# CC2340R5 register map
File version: 1.0
CPU: CM0P 1.0, other endian, MPU, FPU, 3 interrupt priority bits
Registers are 32-bit, read-write, reset 0x0 unless marked. A register's access mark holds for its fields unless they carry their own. Offsets are from the block's base; [hi:lo] are bit positions; {n}, {i} and the like mark numbered series; 'fields as' and 'values as' point back to an identical list.

## ADC — ADC (Analog to Digital Converter) module
Base 0x40050000
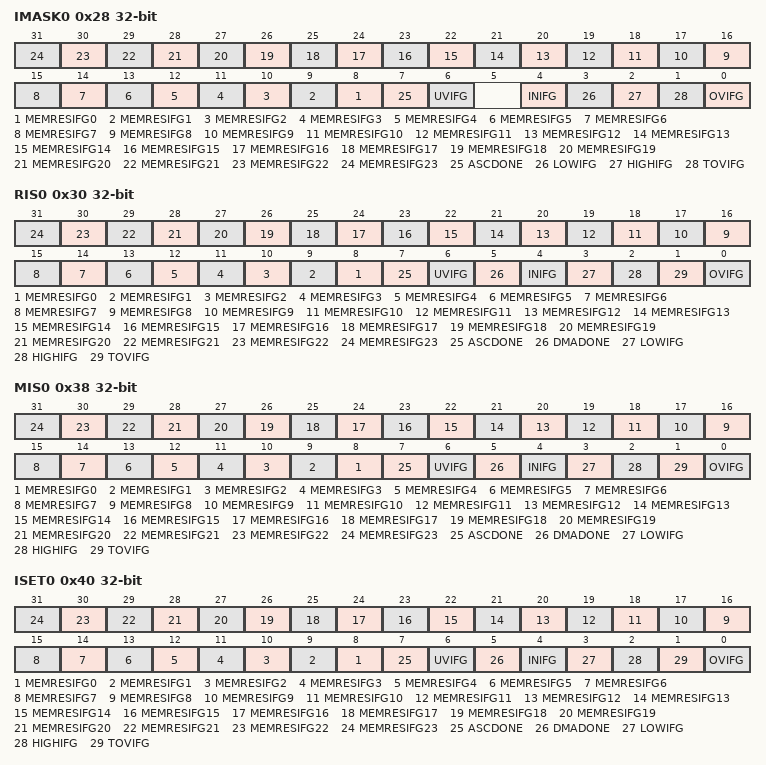
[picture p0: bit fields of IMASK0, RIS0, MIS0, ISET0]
0x28 IMASK0 — Interrupt mask. This register selects interrupt sources which are allowed to pass from RIS0 to MIS0 when the corresponding bit-fields are set to 1.
  [all] fields
    1=ENA (Enable interrupt mask); 0=DIS (Disable interrupt mask)
  [n+8] MEMRESIFG{n} (n=0..23) — [{n+8}:{n+8}] MEMRES{n} conversion result interrupt mask.
  [7] ASCDONE — [7:7] Mask for ASC done raw interrupt flag
  [6] UVIFG — [6:6] Conversion underflow interrupt mask
  [4] INIFG — [4:4] In-range comparator interrupt mask.
  [3] LOWIFG — [3:3] Low threshold compare interrupt mask
  [2] HIGHIFG — [2:2] High threshold compare interrupt mask
  [1] TOVIFG — [1:1] Sequence conversion time overflow interrupt mask
  [0] OVIFG — [0:0] Conversion overflow interrupt mask
0x30 RIS0 — Raw interrupt status. This register reflects the state of all pending interrupts, regardless of masking. This register allows the user to implement a poll scheme. A flag set in this register can be cleared by writing 1 to the corresponding ICLR0 register bit.
  [n+8] MEMRESIFG{n} (n=0..23) — [{n+8}:{n+8}] Raw interrupt status for MEMRES{n}. This bit is set to 1 when MEMRES{n} is loaded with a new conversion result. Reading MEMRES{n} register will clear this bit, or when the corresponding bit in ICLR is set to 1
    1=SET (A new data is ready to be read.); 0=CLR (No new data ready.)
  [7] ASCDONE — [7:7] Raw interrupt flag for ASC done
    1=SET (Interrupt is pending.); 0=CLR (Interrupt is not pending.)
  [6] UVIFG — [6:6] Raw interrupt flag for MEMRESx underflow. This bit is reset to 0 by IIDX read or when corresponding bit in ICLR is set to 1.
    values as ASCDONE
  [5] DMADONE — [5:5] Raw interrupt flag for DMADONE. This bit is reset to 0 by IIDX read or when corresponding bit in ICLR_EX is set to 1.
    values as ASCDONE
  [4] INIFG — [4:4] Mask INIFG in MIS_EX register.
    values as ASCDONE
  [3] LOWIFG — [3:3] Raw interrupt flag for the MEMRESx result register being below than the WCLOWx threshold of the window comparator. This bit is reset to 0 by IIDX read or when corresponding bit in ICLR_EX is set to 1.
    values as ASCDONE
  [2] HIGHIFG — [2:2] Raw interrupt flag for the MEMRESx result register being higher than the WCHIGHx threshold of the window comparator. This bit is reset to 0 by IIDX read or when corresponding bit in ICLR_EX is set to 1.
    values as ASCDONE
  [1] TOVIFG — [1:1] Raw interrupt flag for sequence conversion trigger overflow. This bit is reset to 0 by IIDX read or when corresponding bit in ICLR_EX is set to 1.
    values as ASCDONE
  [0] OVIFG — [0:0] Raw interrupt flag for MEMRESx overflow. This bit is reset to 0 by IIDX read or when corresponding bit in ICLR_EX is set to 1.
    values as ASCDONE
0x38 MIS0 — Masked interrupt status. This is an AND of the IMASK and RIS registers.
  [n+8] MEMRESIFG{n} (n=0..23) — [{n+8}:{n+8}] Raw interrupt status for MEMRES{n}. This bit is set to 1 when MEMRES{n} is loaded with a new conversion result. Reading MEMRES{n} register will clear this bit, or when the corresponding bit in ICLR is set to 1
    values as RIS0.MEMRESIFG0
  [7] ASCDONE — [7:7] Masked interrupt status for ASC done
    values as RIS0.ASCDONE
  [6] UVIFG — [6:6] Raw interrupt flag for MEMRESx underflow. This bit is reset to 0 by IIDX read or when corresponding bit in ICLR is set to 1.
    values as RIS0.ASCDONE
  [5] DMADONE — [5:5] Raw interrupt flag for DMADONE. This bit is reset to 0 by IIDX read or when corresponding bit in ICLR_EX is set to 1.
    values as RIS0.ASCDONE
  [4] INIFG — [4:4] Mask INIFG in MIS_EX register.
    values as RIS0.ASCDONE
  [3] LOWIFG — [3:3] Raw interrupt flag for the MEMRESx result register being below than the WCLOWx threshold of the window comparator. This bit is reset to 0 by IIDX read or when corresponding bit in ICLR_EX is set to 1.
    values as RIS0.ASCDONE
  [2] HIGHIFG — [2:2] Raw interrupt flag for the MEMRESx result register being higher than the WCHIGHx threshold of the window comparator. This bit is reset to 0 by IIDX read or when corresponding bit in ICLR_EX is set to 1.
    values as RIS0.ASCDONE
  [1] TOVIFG — [1:1] Raw interrupt flag for sequence conversion timeout overflow. This bit is reset to 0 by IIDX read or when corresponding bit in ICLR_EX is set to 1.
    values as RIS0.ASCDONE
  [0] OVIFG — [0:0] Raw interrupt flag for MEMRESx overflow. This bit is reset to 0 by IIDX read or when corresponding bit in ICLR_EX is set to 1.
    values as RIS0.ASCDONE
0x40 ISET0 — Interrupt set. Allows interrupts to be set by software (useful in diagnostics and safety checks). Writing a 1 to a bit in ISET0 will set the event and therefore the related RIS bit also gets set. If the interrupt is enabled through the mask, then the corresponding MIS bit is also set.
  [n+8] MEMRESIFG{n} (n=0..23) — [{n+8}:{n+8}] Raw interrupt status for MEMRES{n}. This bit is set to 1 when MEMRES{n} is loaded with a new conversion result. Reading MEMRES{n} register will clear this bit, or when the corresponding bit in ICLR is set to 1
    1=SET (A new data is ready to be read.); 0=NO_EFFECT (No new data ready.)
  [7] ASCDONE — [7:7] Set ASC done flag in RIS
    1=SET (Interrupt is pending.); 0=NO_EFFECT (Interrupt is not pending.)
  [6] UVIFG — [6:6] Raw interrupt flag for MEMRESx underflow. This bit is reset to 0 by IIDX read or when corresponding bit in ICLR_EX is set to 1.
    values as ASCDONE
  [5] DMADONE — [5:5] Raw interrupt flag for DMADONE. This bit is reset to 0 by IIDX read or when corresponding bit in ICLR_EX is set to 1.
    values as ASCDONE
  [4] INIFG — [4:4] Mask INIFG in MIS_EX register.
    values as ASCDONE
  [3] LOWIFG — [3:3] Raw interrupt flag for the MEMRESx result register being below than the WCLOWx threshold of the window comparator. This bit is reset to 0 by IIDX read or when corresponding bit in ICLR_EX is set to 1.
    values as ASCDONE
  [2] HIGHIFG — [2:2] Raw interrupt flag for the MEMRESx result register being higher than the WCHIGHx threshold of the window comparator. This bit is reset to 0 by IIDX read or when corresponding bit in ICLR_EX is set to 1.
    values as ASCDONE
  [1] TOVIFG — [1:1] Raw interrupt flag for sequence conversion timeout overflow. This bit is reset to 0 by IIDX read or when corresponding bit in ICLR_EX is set to 1.
    values as ASCDONE
  [0] OVIFG — [0:0] Raw interrupt flag for MEMRESx overflow. This bit is reset to 0 by IIDX read or when corresponding bit in ICLR_EX is set to 1.
    values as ASCDONE
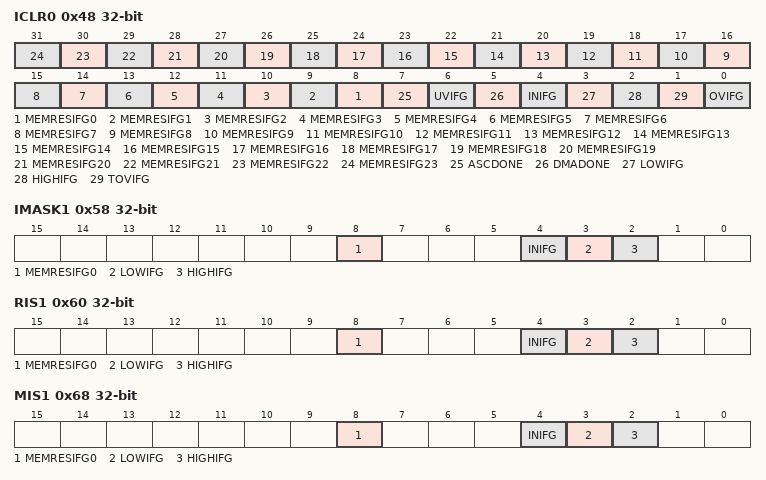
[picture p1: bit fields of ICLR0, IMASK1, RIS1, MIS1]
0x48 ICLR0 — Interrupt clear. Write a 1 to clear corresponding Interrupt.
  [n+8] MEMRESIFG{n} (n=0..23) — [{n+8}:{n+8}] Raw interrupt status for MEMRES{n}. This bit is set to 1 when MEMRES{n} is loaded with a new conversion result. Reading MEMRES{n} register will clear this bit, or when the corresponding bit in ICLR is set to 1
    1=CLR (A new data is ready to be read.); 0=NO_EFFECT (No new data ready.)
  [7] ASCDONE — [7:7] Clear ASC done flag in RIS
    1=CLR (Interrupt is pending.); 0=NO_EFFECT (Interrupt is not pending.)
  [6] UVIFG — [6:6] Raw interrupt flag for MEMRESx underflow. This bit is reset to 0 by IIDX read or when corresponding bit in ICLR_EX is set to 1.
    values as ASCDONE
  [5] DMADONE — [5:5] Raw interrupt flag for DMADONE. This bit is reset to 0 by IIDX read or when corresponding bit in ICLR_EX is set to 1.
    values as ASCDONE
  [4] INIFG — [4:4] Mask INIFG in MIS_EX register.
    values as ASCDONE
  [3] LOWIFG — [3:3] Raw interrupt flag for the MEMRESx result register being below than the WCLOWx threshold of the window comparator. This bit is reset to 0 by IIDX read or when corresponding bit in ICLR_EX is set to 1.
    values as ASCDONE
  [2] HIGHIFG — [2:2] Raw interrupt flag for the MEMRESx result register being higher than the WCHIGHx threshold of the window comparator. This bit is reset to 0 by IIDX read or when corresponding bit in ICLR_EX is set to 1.
    values as ASCDONE
  [1] TOVIFG — [1:1] Raw interrupt flag for sequence conversion timeout overflow. This bit is reset to 0 by IIDX read or when corresponding bit in ICLR_EX is set to 1.
    values as ASCDONE
  [0] OVIFG — [0:0] Raw interrupt flag for MEMRESx overflow. This bit is reset to 0 by IIDX read or when corresponding bit in ICLR_EX is set to 1.
    values as ASCDONE
0x58 IMASK1 — Interrupt Mask. If a bit is set, then corresponding interrupt is un-masked. Un-masking the interrupt causes the raw interrupt to be visible in IIDX, as well as MIS.
  [8] MEMRESIFG0 — [8:8] Raw interrupt status for MEMRES0. This bit is set to 1 when MEMRES0 is loaded with a new conversion result. Reading MEMRES0 register will clear this bit, or when the corresponding bit in ICLR is set to 1
    values as RIS0.MEMRESIFG0
  [4] INIFG — [4:4] Mask INIFG in MIS_EX register.
    values as RIS0.ASCDONE
  [3] LOWIFG — [3:3] Raw interrupt flag for the MEMRESx result register being below than the WCLOWx threshold of the window comparator. This bit is reset to 0 by IIDX read or when corresponding bit in ICLR_EX is set to 1.
    values as RIS0.ASCDONE
  [2] HIGHIFG — [2:2] Raw interrupt flag for the MEMRESx result register being higher than the WCHIGHx threshold of the window comparator. This bit is reset to 0 by IIDX read or when corresponding bit in ICLR_EX is set to 1.
    values as RIS0.ASCDONE
0x60 RIS1 — Raw interrupt status. Reflects all pending interrupts, regardless of masking. The RIS1 register allows the user to implement a poll scheme. A flag set in this register can be cleared by writing 1 to the ICLR register bit even if the corresponding IMASK bit is not enabled.
  fields as IMASK1
0x68 MIS1 — Masked interrupt status. This is an AND of the IMASK and RIS registers.
  fields as IMASK1
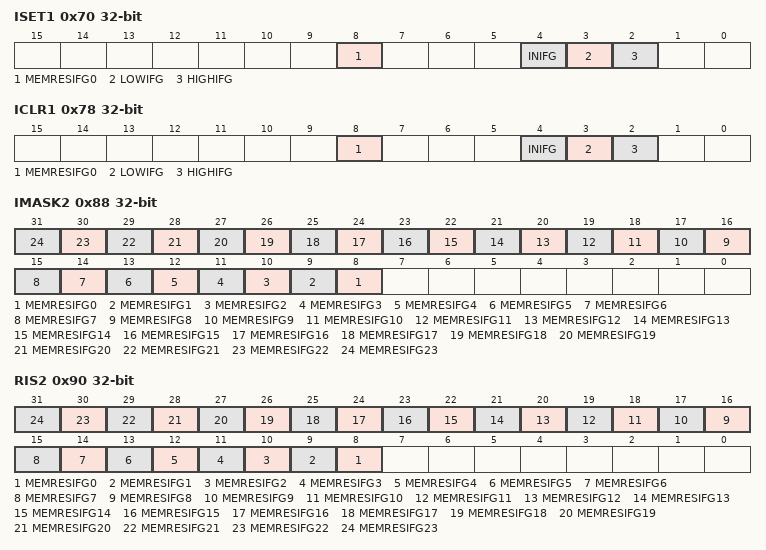
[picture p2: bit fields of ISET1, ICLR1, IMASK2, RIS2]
0x70 ISET1 — Interrupt set. Allows interrupts to be set by software (useful in diagnostics and safety checks). Writing a 1 to a bit in ISET1 will set the event and therefore the related RIS bit also gets set. If the interrupt is enabled through the mask, then the corresponding MIS bit is also set.
  [8] MEMRESIFG0 — [8:8] Raw interrupt status for MEMRES0. This bit is set to 1 when MEMRES0 is loaded with a new conversion result. Reading MEMRES0 register will clear this bit, or when the corresponding bit in ICLR is set to 1
    values as ISET0.MEMRESIFG0
  [4] INIFG — [4:4] Mask INIFG in MIS_EX register.
    values as ISET0.ASCDONE
  [3] LOWIFG — [3:3] Raw interrupt flag for the MEMRESx result register being below than the WCLOWx threshold of the window comparator. This bit is reset to 0 by IIDX read or when corresponding bit in ICLR_EX is set to 1.
    values as ISET0.ASCDONE
  [2] HIGHIFG — [2:2] Raw interrupt flag for the MEMRESx result register being higher than the WCHIGHx threshold of the window comparator. This bit is reset to 0 by IIDX read or when corresponding bit in ICLR_EX is set to 1.
    values as ISET0.ASCDONE
0x78 ICLR1 — Interrupt clear. Write a 1 to clear corresponding Interrupt.
  [8] MEMRESIFG0 — [8:8] Raw interrupt status for MEMRES0. This bit is set to 1 when MEMRES0 is loaded with a new conversion result. Reading MEMRES0 register will clear this bit, or when the corresponding bit in ICLR is set to 1
    values as ICLR0.MEMRESIFG0
  [4] INIFG — [4:4] Mask INIFG in MIS_EX register.
    values as ICLR0.ASCDONE
  [3] LOWIFG — [3:3] Raw interrupt flag for the MEMRESx result register being below than the WCLOWx threshold of the window comparator. This bit is reset to 0 by IIDX read or when corresponding bit in ICLR_EX is set to 1.
    values as ICLR0.ASCDONE
  [2] HIGHIFG — [2:2] Raw interrupt flag for the MEMRESx result register being higher than the WCHIGHx threshold of the window comparator. This bit is reset to 0 by IIDX read or when corresponding bit in ICLR_EX is set to 1.
    values as ICLR0.ASCDONE
0x88 IMASK2 — Interrupt Mask. If a bit is set, then corresponding interrupt is un-masked. Un-masking the interrupt causes the raw interrupt to be visible in IIDX, as well as MIS.
  [all] fields
    values as RIS0.MEMRESIFG0
  [n+8] MEMRESIFG{n} (n=0..23) — [{n+8}:{n+8}] Raw interrupt status for MEMRES{n}. This bit is set to 1 when MEMRES{n} is loaded with a new conversion result. Reading MEMRES{n} register will clear this bit, or when the corresponding bit in ICLR is set to 1
0x90 RIS2 — Raw interrupt status. Reflects all pending interrupts, regardless of masking. The RIS2 register allows the user to implement a poll scheme. A flag set in this register can be cleared by writing 1 to the ICLR register bit even if the corresponding IMASK bit is not enabled.
  fields as IMASK2
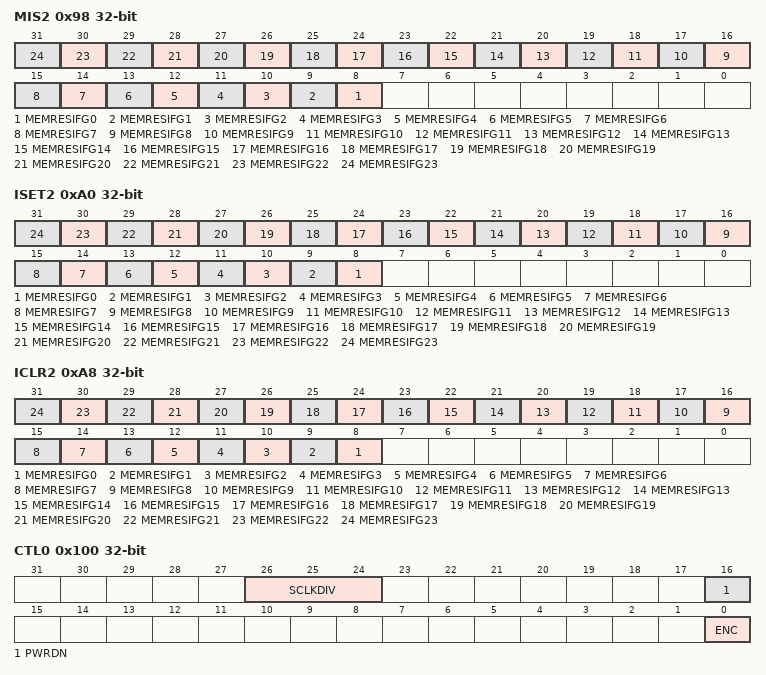
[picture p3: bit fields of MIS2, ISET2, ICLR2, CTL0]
0x98 MIS2 — Extension of Masked interrupt status. This is an AND of the IMASK and RIS registers.
  fields as IMASK2
0xA0 ISET2 — Interrupt set. Allows interrupts to be set by software (useful in diagnostics and safety checks). Writing a 1 to a bit in ISET2 will set the event and therefore the related RIS bit also gets set. If the interrupt is enabled through the mask, then the corresponding MIS bit is also set.
  [all] fields
    values as ISET0.MEMRESIFG0
  [n+8] MEMRESIFG{n} (n=0..23) — [{n+8}:{n+8}] Raw interrupt status for MEMRES{n}. This bit is set to 1 when MEMRES{n} is loaded with a new conversion result. Reading MEMRES{n} register will clear this bit, or when the corresponding bit in ICLR is set to 1
0xA8 ICLR2 — Interrupt clear. Write a 1 to clear corresponding Interrupt.
  [all] fields
    values as ICLR0.MEMRESIFG0
  [n+8] MEMRESIFG{n} (n=0..23) — [{n+8}:{n+8}] Raw interrupt status for MEMRES{n}. This bit is set to 1 when MEMRES{n} is loaded with a new conversion result. Reading MEMRES{n} register will clear this bit, or when the corresponding bit in ICLR is set to 1
0x100 CTL0 — Control Register 0
  [26:24] SCLKDIV — [26:24] Sample clock divider
    7=DIV_BY_48 (Divide clock source by 48); 6=DIV_BY_32 (Divide clock source by 32); 5=DIV_BY_24 (Divide clock source by 24); 4=DIV_BY_16 (Divide clock source by 16); 3=DIV_BY_8 (Divide clock source by 8); 2=DIV_BY_4 (Divide clock source by 4); 1=DIV_BY_2 (Divide clock source by 2); 0=DIV_BY_1 (Do not divide clock source)
  [16] PWRDN — [16:16] Power down policy
    1=MANUAL (ADC remains powered on as long as it is enabled through software.); 0=AUTO (ADC is powered down on completion of a conversion if there is no pending trigger)
  [0] ENC — [0:0] Enable conversion
    1=ON (Conversion enabled. ADC sequencer waits for valid trigger (software or hardware).); 0=OFF (Conversion disabled. ENC change from ON to OFF will abort single or repeat sequence on a MEMCTLx boundary. The current conversion will finish and result stored in corresponding MEMRESx.)
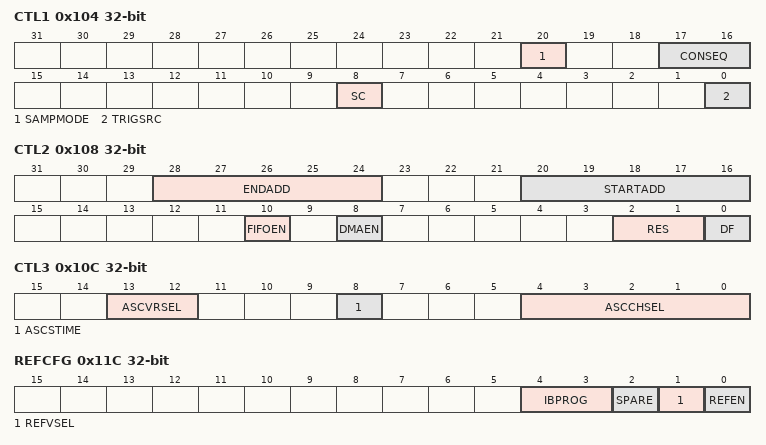
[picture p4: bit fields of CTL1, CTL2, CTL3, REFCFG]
0x104 CTL1 — Control Register 1
  [20] SAMPMODE — [20:20] Sample mode. This bit selects the source of the sampling signal. MANUAL option is not valid when TRIGSRC is selected as hardware event trigger.
    1=MANUAL (Software trigger is used as sample signal); 0=AUTO (Sample timer high phase is used as sample signal)
  [17:16] CONSEQ — [17:16] Conversion sequence mode
    3=REPEATSEQUENCE (ADC channel sequence pointed by STARTADD and ENDADD will be converted repeatedly); 2=REPEATSINGLE (ADC channel in MEMCTLx pointed by STARTADD will be converted repeatedly); 1=SEQUENCE (ADC channel sequence pointed by STARTADD and ENDADD will be converted once); 0=SINGLE (ADC channel in MEMCTLx pointed by STARTADD will be converted once)
  [8] SC — [8:8] Start of conversion
    1=START (When SAMPMODE is set to MANUAL, setting this bit will start the sample phase. Sample phase will last as long as this bit is set. When SAMPMODE is set to AUTO, setting this bit will trigger the timer based sample time.); 0=STOP (When SAMPMODE is set to MANUAL, clearing this bit will end the sample phase and the conversion phase will start. When SAMPMODE is set to AUTO, writing 0 has no effect.)
  [0] TRIGSRC — [0:0] Sample trigger source
    1=EVENT (Hardware event trigger); 0=SOFTWARE (Software trigger)
0x108 CTL2 — Control Register 2
  [28:24] ENDADD — [28:24] Sequence end address. These bits select which MEMCTLx is the last one for the sequence mode. The value of ENDADD is 0x00 to 0x17, corresponding to MEMRES0 to MEMRES23.
    {v}=ADDR_{v:02} (MEMCTL{v} is selected as end address of sequence.) (v=0..23)
  [20:16] STARTADD — [20:16] Sequencer start address. These bits select which MEMCTLx is used for single conversion or as first MEMCTL for sequence mode. The value of STARTADD is 0x00 to 0x17, corresponding to MEMRES0 to MEMRES23.
    {v}=ADDR_{v:02} (MEMCTL{v} is selected as start address of a sequence or for a single conversion.) (v=0..23)
  [10] FIFOEN — [10:10] Enable FIFO based operation
    1=ENABLE; 0=DISABLE
  [8] DMAEN — [8:8] Enable DMA trigger for data transfer. Note: DMAEN bit is cleared by hardware based on DMA done signal at the end of data transfer. Software has to re-enable DMAEN bit for ADC to generate DMA triggers.
    1=ENABLE (DMA trigger enabled); 0=DISABLE (DMA trigger not enabled)
  [2:1] RES — [2:1] Resolution. These bits define the resolutoin of ADC conversion result. Note : A value of 3 defaults to 12-bits resolution.
    2=BIT_8 (8-bits resolution); 1=BIT_10 (10-bits resolution); 0=BIT_12 (12-bits resolution)
  [0] DF — [0:0] Data read-back format. Data is always stored in binary unsigned format.
    1=SIGNED (Digital result reads Signed Binary. (2s complement), left aligned.); 0=UNSIGNED (Digital result reads as Binary Unsigned.)
0x10C CTL3 — Control Register 3. This register is used to configure ADC for ad-hoc single conversion.
  [13:12] ASCVRSEL — [13:12] Selects voltage reference for ASC operation. AREF- must be connected to on-board ground when external reference option is selected. Note: Writing value 0x3 defaults to INTREF.
    2=INTREF (Internal reference); 1=EXTREF (External reference from AREF+/AREF- pins); 0=VDDS (VDDS reference)
  [8] ASCSTIME — [8:8] ASC sample time compare value select. This is used to select between SCOMP0 and SCOMP1 registers for ASC operation.
    1=SEL_SCOMP1 (Select SCOMP1); 0=SEL_SCOMP0 (Select SCOMP0)
  [4:0] ASCCHSEL — [4:0] ASC channel select
    {v}=CHAN_{v} (Selects channel {v}) (v=0..31)
0x114 SCOMP0 — Sample time compare 0 register. Specifies the sample time, in number of ADC sample clock cycles. CTL0.ENC must be set to 0 to write to this register.
  [9:0] VAL — [9:0] Specifies the number of sample clocks. When VAL = 0 or 1, number of sample clocks = Sample clock divide value. When VAL $gt; 1, number of sample clocks = VAL x Sample clock divide value. Note: Sample clock divide value is not the value written to SCLKDIV but the actual divide value (SCLKDIV = 2 implies divide value is 4). Example: VAL = 4, SCLKDIV = 3 implies 32 sample clock cycles.
0x118 SCOMP1 — Sample time compare 1 register. Specifies the sample time, in number of ADC sample clock cycles. CTL0.ENC must be set to 0 to write to this register.
  fields as SCOMP0
0x11C REFCFG — Reference buffer configuration register
  [4:3] IBPROG — [4:3] Configures reference buffer bias current output value
    3=0.67uA; 2=2uA; 1=0.5uA; 0=1uA
  [2] SPARE — [2:2] Spare bit
  [1] REFVSEL — [1:1] Configures reference buffer output voltage
    1=V1P4 (REFBUF generates 1.4V output); 0=V2P5 (REFBUF generates 2.5V output)
  [0] REFEN — [0:0] Reference buffer enable
    1=ENABLE; 0=DISABLE
0x148 WCLOW — Window Comparator Low Threshold Register. The data format that is used to write and read WCLOW depends on the value of DF bit in CTL2 register. CTL0.ENC must be 0 to write to this register. Note: Change in ADC data format or resolution does not reset WCLOW.
  [15:0] DATA — [15:0] If DF = 0, unsigned binary format has to be used. The value based on the resolution has to be right aligned with the MSB on the left. For 10-bits and 8-bits resolution, unused bits have to be 0s. If DF = 1, 2s-complement format has to be used. The value based on the resolution has to be left aligned with the LSB on the right. For 10-bits and 8-bits resolution, unused bits have to be 0s.
0x150 WCHIGH — Window Comparator High Threshold Register. The data format that is used to write and read WCHIGH depends on the value of DF bit in CTL2 register. CTL0.ENC must be 0 to write to this register. Note: Change in ADC data format or resolution does not reset WCHIGH.
  [15:0] DATA — [15:0] If DF = 0, unsigned binary format has to be used. The threshold value has to be right aligned, with the MSB on the left. For 10-bits and 8-bits resolution, unused bit have to be 0s. If DF = 1, 2s-complement format has to be used. The value based on the resolution has to be left aligned with the LSB on the right. For 10-bits and 8-bits resolution, unused bit have to be 0s.
0x160 FIFODATA — FIFO data register. This is a virtual register used to do read from FIFO.
  [31:0] DATA — [31:0] Read from this data field returns the ADC sample from FIFO.
0x170 ASCRES — ASC result register
  [15:0] DATA ro — [15:0] Result of ADC ad-hoc single conversion. If DF = 0, unsigned binary: The conversion result is right aligned. In 10 and 8 bit modes, the unused MSB bits are forced to 0. If DF = 1, 2s-complement format: The conversion result is left aligned. In 10 and 8 bit modes, the unused LSB bits are forced to 0. The data is stored in the right-justified format and is converted to the left-justified 2s-complement format during read back.
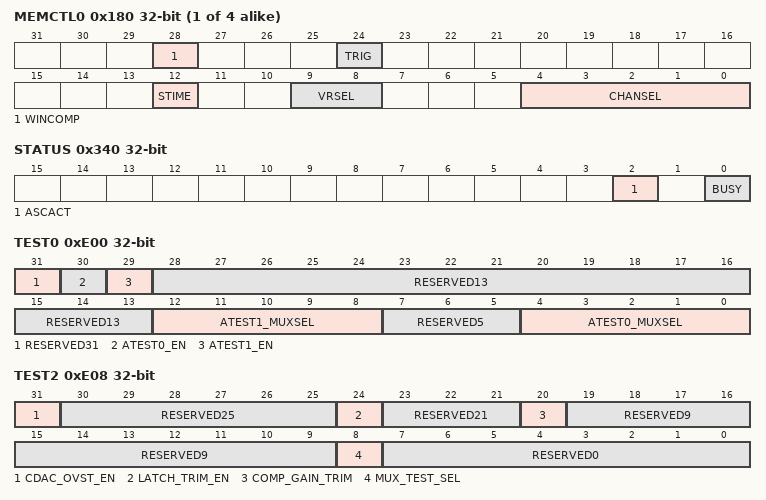
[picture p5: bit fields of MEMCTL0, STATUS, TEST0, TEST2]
{0x180+4i} MEMCTL{i} (i=0..3) — Conversion Memory Control Register {i}. CTL0.ENC must be set to 0 to write to this register.
  [28] WINCOMP — [28:28] Enable window comparator.
    1=ENABLE; 0=DISABLE
  [24] TRIG — [24:24] Trigger policy. Indicates if a trigger will be needed to step to the next MEMCTL in the sequence or to perform next conversion in the case of repeat single channel conversions.
    1=TRIGGER_NEXT (Next conversion requires a trigger); 0=AUTO_NEXT (Next conversion is automatic)
  [12] STIME — [12:12] Selects the source of sample timer period between SCOMP0 and SCOMP1.
    1=SEL_SCOMP1 (Select SCOMP1); 0=SEL_SCOMP0 (Select SCOMP0)
  [9:8] VRSEL — [9:8] Voltage reference selection. AREF- must be connected to on-board ground when external reference option is selected. Note: Writing value 0x3 defaults to INTREF.
    values as CTL3.ASCVRSEL
  [4:0] CHANSEL — [4:0] Input channel select.
    {v}=CHAN_{v} (Selects channel {v}) (v=0..31)
{0x280+4i} MEMRES{i} (i=0..3) — Memory Result Register {i}
  [15:0] DATA — [15:0] If DF = 0, unsigned binary: The conversion results are right aligned. In 10 and 8 bit modes, the unused MSB bits are forced to 0. If DF = 1, 2s-complement format: The conversion results are left aligned. In 10 and 8 bit modes, the unused LSB bits are forced to 0. The data is stored in the right-justified format and is converted to the left-justified 2s-complement format during read back.
0x340 STATUS
  [2] ASCACT ro — [2:2] ASC active
    1=ACTIVE (ASC active); 0=IDLE (Idle or done)
  [0] BUSY ro — [0:0] Busy. This bit indicates that an active ADC sample or conversion operation is in progress.
    1=ACTIVE (ADC sampling or conversion is in progress.); 0=IDLE (No ADC sampling or conversion in progress.)
0xE00 TEST0 — Internal. Only to be used through TI provided API.
  [31] RESERVED31 ro — [31:31] Internal. Only to be used through TI provided API.
  [30] ATEST0_EN — [30:30] Internal. Only to be used through TI provided API.
    1=ENABLE (Internal. Only to be used through TI provided API.); 0=DISABLE (Internal. Only to be used through TI provided API.)
  [29] ATEST1_EN — [29:29] Internal. Only to be used through TI provided API.
    values as ATEST0_EN
  [28:13] RESERVED13 ro — [28:13] Internal. Only to be used through TI provided API.
  [12:8] ATEST1_MUXSEL — [12:8] Internal. Only to be used through TI provided API.
    16=Internal. Only to be used through TI provided API.; 8=Internal. Only to be used through TI provided API.; 4=Internal. Only to be used through TI provided API.; 2=Internal. Only to be used through TI provided API.; 1=Internal. Only to be used through TI provided API.
  [7:5] RESERVED5 ro — [7:5] Internal. Only to be used through TI provided API.
  [4:0] ATEST0_MUXSEL — [4:0] Internal. Only to be used through TI provided API.
    values as ATEST1_MUXSEL
0xE04 TEST1 — Test 1 register. This is used to select ADC internal signals on DTB.
  [4:0] DTB_MUXSEL — [4:0] DTB mux select.
0xE08 TEST2 — Internal. Only to be used through TI provided API.
  [31] CDAC_OVST_EN — [31:31] Internal. Only to be used through TI provided API.
  [30:25] RESERVED25 ro — [30:25] Internal. Only to be used through TI provided API.
  [24] LATCH_TRIM_EN — [24:24] Internal. Only to be used through TI provided API.
  [23:21] RESERVED21 ro — [23:21] Internal. Only to be used through TI provided API.
  [20] COMP_GAIN_TRIM — [20:20] Internal. Only to be used through TI provided API.
  [19:9] RESERVED9 ro — [19:9] Internal. Only to be used through TI provided API.
  [8] MUX_TEST_SEL — [8:8] Internal. Only to be used through TI provided API.
  [7:0] RESERVED0 ro — [7:0] Internal. Only to be used through TI provided API.
0xE0C TEST3 — ADC CAL Accumulation Register
  [31:0] CAL_ACUML — [31:0] Accumulation of # samples during Calibration step
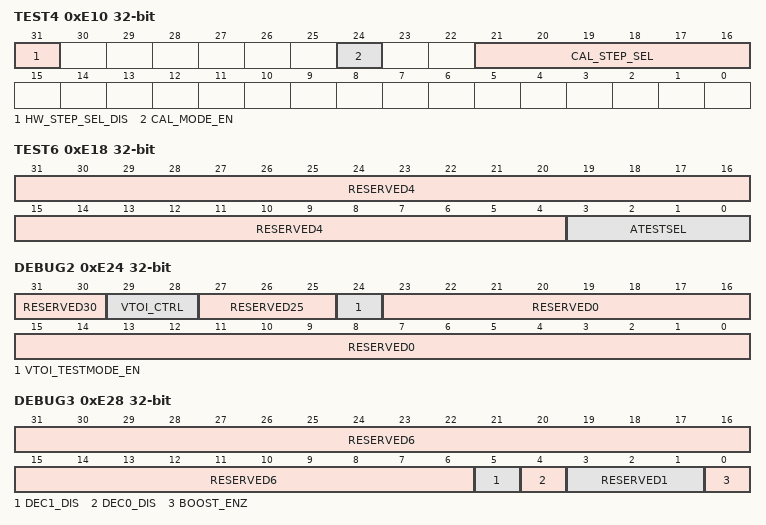
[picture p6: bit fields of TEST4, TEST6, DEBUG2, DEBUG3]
0xE10 TEST4 — CAL Control register: Average Sample count, Step number, Recal En and Debug option to override ull_usc_ulpadchp_dft_i$lt;26:0$gt;.
  [31] HW_STEP_SEL_DIS — [31:31] By Enabling this bit, DLC written value overwritten of ull_usc_ulpadchp_dft_i$lt;26:0$gt; from TEST7 regsiter. This is for debug.
  [24] CAL_MODE_EN — [24:24] ADC CDAC Calibration mode enable
  [21:16] CAL_STEP_SEL — [21:16] ADC CAL STEP SELECTION
0xE14 TEST5 — This regsiter updated ull_usc_ulpadchp_dft_i[26:0] value if Test 5: HW_STEP_SEL_DIS bit enable
  [9:0] CAL_CAP_CTL — [9:0] This regsiter updated ull_usc_ulpadchp_dft_i[26:0] value if Test 5: HW_STEP_SEL_DIS bit enabled ull_usc_ulpadchp_dft_i[26:0]
0xE18 TEST6 — Internal. Only to be used through TI provided API.
  [31:4] RESERVED4 ro — [31:4] Internal. Only to be used through TI provided API.
  [3:0] ATESTSEL — [3:0] Internal. Only to be used through TI provided API.
    8=Internal. Only to be used through TI provided API.; 4=Internal. Only to be used through TI provided API.; 2=Internal. Only to be used through TI provided API.; 1=Internal. Only to be used through TI provided API.; 0=Internal. Only to be used through TI provided API.
0xE20 DEBUG1 reset 0x801000 — Internal. Only to be used through TI provided API.
  [31:0] CTRL — [31:0] Internal. Only to be used through TI provided API.
0xE24 DEBUG2 — Internal. Only to be used through TI provided API.
  [31:30] RESERVED30 ro — [31:30] Internal. Only to be used through TI provided API.
  [29:28] VTOI_CTRL — [29:28] Internal. Only to be used through TI provided API.
  [27:25] RESERVED25 ro — [27:25] Internal. Only to be used through TI provided API.
  [24] VTOI_TESTMODE_EN — [24:24] Internal. Only to be used through TI provided API.
  [23:0] RESERVED0 ro — [23:0] Internal. Only to be used through TI provided API.
0xE28 DEBUG3 — Internal. Only to be used through TI provided API.
  [31:6] RESERVED6 ro — [31:6] Internal. Only to be used through TI provided API.
  [5] DEC1_DIS — [5:5] Internal. Only to be used through TI provided API.
  [4] DEC0_DIS — [4:4] Internal. Only to be used through TI provided API.
  [3:1] RESERVED1 ro — [3:1] Internal. Only to be used through TI provided API.
  [0] BOOST_ENZ — [0:0] Internal. Only to be used through TI provided API.
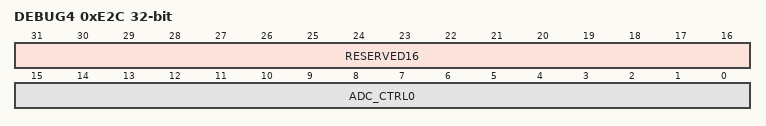
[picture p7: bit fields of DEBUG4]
0xE2C DEBUG4 — Internal. Only to be used through TI provided API.
  [31:16] RESERVED16 ro — [31:16] Internal. Only to be used through TI provided API.
  [15:0] ADC_CTRL0 — [15:0] Internal. Only to be used through TI provided API.
